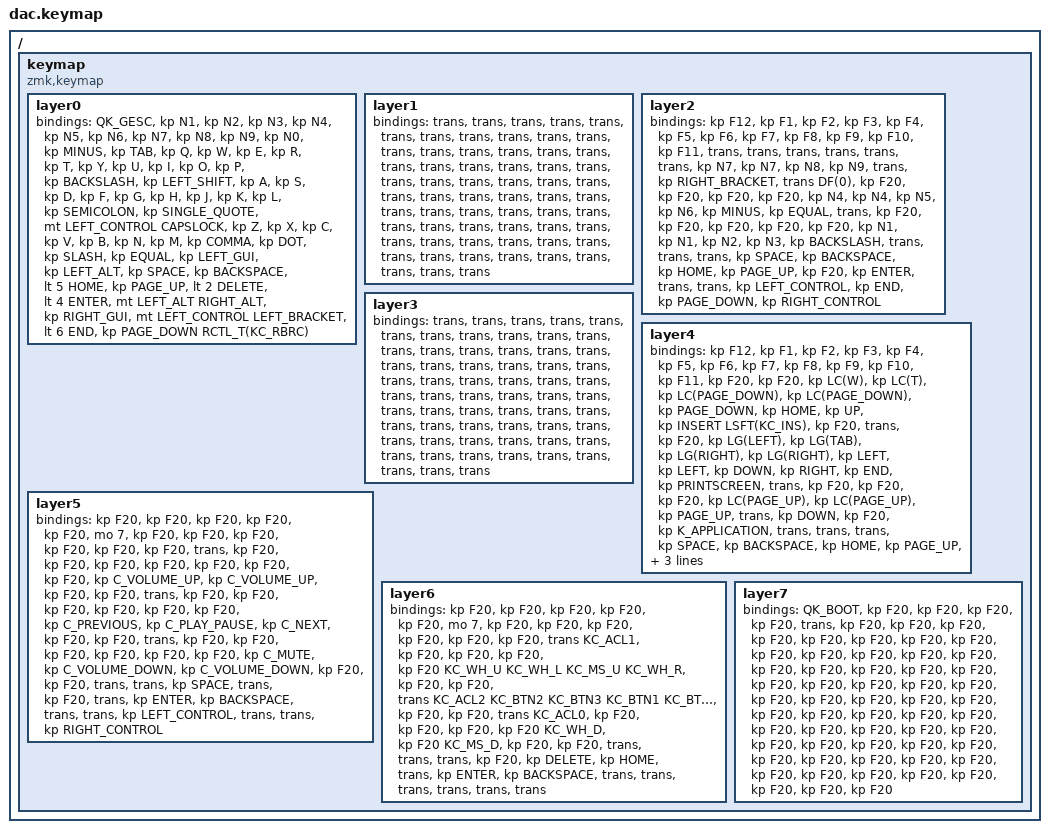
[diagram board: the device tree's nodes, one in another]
/*
  * Copyright (c) 2020 The ZMK Contributors
  *
  * SPDX-License-Identifier: MIT
  */

  #include <behaviors.dtsi>
  #include <dt-bindings/zmk/keys.h>
  #include <dt-bindings/zmk/bt.h>
  #include <dt-bindings/zmk/ext_power.h>

  / {
    keymap {
      compatible = "zmk,keymap";
  layer0 {
          bindings = <
          QK_GESC &kp N1 &kp N2 &kp N3 &kp N4 &kp N5 &kp N6 &kp N7 &kp N8 &kp N9 &kp N0 &kp MINUS &kp TAB &kp Q &kp W &kp E &kp R &kp T &kp Y &kp U &kp I &kp O &kp P &kp BACKSLASH &kp LEFT_SHIFT &kp A &kp S &kp D &kp F &kp G &kp H &kp J &kp K &kp L &kp SEMICOLON &kp SINGLE_QUOTE &mt LEFT_CONTROL CAPSLOCK &kp Z &kp X &kp C &kp V &kp B &kp N &kp M &kp COMMA &kp DOT &kp SLASH &kp EQUAL &kp LEFT_GUI &kp LEFT_ALT &kp SPACE &kp BACKSPACE &lt 5 HOME &kp PAGE_UP &lt 2 DELETE &lt 4 ENTER &mt LEFT_ALT RIGHT_ALT &kp RIGHT_GUI &mt LEFT_CONTROL LEFT_BRACKET &lt 6 END &kp PAGE_DOWN RCTL_T(KC_RBRC)
          >;
        };layer1 {
          bindings = <
          &trans &trans &trans &trans &trans &trans &trans &trans &trans &trans &trans &trans &trans &trans &trans &trans &trans &trans &trans &trans &trans &trans &trans &trans &trans &trans &trans &trans &trans &trans &trans &trans &trans &trans &trans &trans &trans &trans &trans &trans &trans &trans &trans &trans &trans &trans &trans &trans &trans &trans &trans &trans &trans &trans &trans &trans &trans &trans &trans &trans &trans &trans
          >;
        };layer2 {
          bindings = <
          &kp F12 &kp F1 &kp F2 &kp F3 &kp F4 &kp F5 &kp F6 &kp F7 &kp F8 &kp F9 &kp F10 &kp F11 &trans &trans &trans &trans &trans &trans &kp N7 &kp N7 &kp N8 &kp N9 &trans &kp RIGHT_BRACKET &trans DF(0) &kp F20 &kp F20 &kp F20 &kp F20 &kp N4 &kp N4 &kp N5 &kp N6 &kp MINUS &kp EQUAL &trans &kp F20 &kp F20 &kp F20 &kp F20 &kp F20 &kp N1 &kp N1 &kp N2 &kp N3 &kp BACKSLASH &trans &trans &trans &kp SPACE &kp BACKSPACE &kp HOME &kp PAGE_UP &kp F20 &kp ENTER &trans &trans &kp LEFT_CONTROL &kp END &kp PAGE_DOWN &kp RIGHT_CONTROL
          >;
        };layer3 {
          bindings = <
          &trans &trans &trans &trans &trans &trans &trans &trans &trans &trans &trans &trans &trans &trans &trans &trans &trans &trans &trans &trans &trans &trans &trans &trans &trans &trans &trans &trans &trans &trans &trans &trans &trans &trans &trans &trans &trans &trans &trans &trans &trans &trans &trans &trans &trans &trans &trans &trans &trans &trans &trans &trans &trans &trans &trans &trans &trans &trans &trans &trans &trans &trans
          >;
        };layer4 {
          bindings = <
          &kp F12 &kp F1 &kp F2 &kp F3 &kp F4 &kp F5 &kp F6 &kp F7 &kp F8 &kp F9 &kp F10 &kp F11 &kp F20 &kp F20 &kp LC(W) &kp LC(T) &kp LC(PAGE_DOWN) &kp LC(PAGE_DOWN) &kp PAGE_DOWN &kp HOME &kp UP &kp INSERT LSFT(KC_INS) &kp F20 &trans &kp F20 &kp LG(LEFT) &kp LG(TAB) &kp LG(RIGHT) &kp LG(RIGHT) &kp LEFT &kp LEFT &kp DOWN &kp RIGHT &kp END &kp PRINTSCREEN &trans &kp F20 &kp F20 &kp F20 &kp LC(PAGE_UP) &kp LC(PAGE_UP) &kp PAGE_UP &trans &kp DOWN &kp F20 &kp K_APPLICATION &trans &trans &trans &kp SPACE &kp BACKSPACE &kp HOME &kp PAGE_UP &kp DELETE &kp F20 &trans &trans &kp LEFT_CONTROL &kp END &kp PAGE_DOWN &kp RIGHT_CONTROL
          >;
        };layer5 {
          bindings = <
          &kp F20 &kp F20 &kp F20 &kp F20 &kp F20 &mo 7 &kp F20 &kp F20 &kp F20 &kp F20 &kp F20 &kp F20 &trans &kp F20 &kp F20 &kp F20 &kp F20 &kp F20 &kp F20 &kp F20 &kp C_VOLUME_UP &kp C_VOLUME_UP &kp F20 &kp F20 &trans &kp F20 &kp F20 &kp F20 &kp F20 &kp F20 &kp F20 &kp C_PREVIOUS &kp C_PLAY_PAUSE &kp C_NEXT &kp F20 &kp F20 &trans &kp F20 &kp F20 &kp F20 &kp F20 &kp F20 &kp F20 &kp C_MUTE &kp C_VOLUME_DOWN &kp C_VOLUME_DOWN &kp F20 &kp F20 &trans &trans &kp SPACE &trans &kp F20 &trans &kp ENTER &kp BACKSPACE &trans &trans &kp LEFT_CONTROL &trans &trans &kp RIGHT_CONTROL
          >;
        };layer6 {
          bindings = <
          &kp F20 &kp F20 &kp F20 &kp F20 &kp F20 &mo 7 &kp F20 &kp F20 &kp F20 &kp F20 &kp F20 &kp F20 &trans KC_ACL1 &kp F20 &kp F20 &kp F20 &kp F20 KC_WH_U KC_WH_L KC_MS_U KC_WH_R &kp F20 &kp F20 &trans KC_ACL2 KC_BTN2 KC_BTN3 KC_BTN1 KC_BTN1 KC_MS_L KC_MS_L KC_MS_D KC_MS_R &kp F20 &kp F20 &trans KC_ACL0 &kp F20 &kp F20 &kp F20 &kp F20 KC_WH_D &kp F20 KC_MS_D &kp F20 &kp F20 &trans &trans &trans &kp F20 &kp DELETE &kp HOME &trans &kp ENTER &kp BACKSPACE &trans &trans &trans &trans &trans &trans
          >;
        };layer7 {
          bindings = <
          QK_BOOT &kp F20 &kp F20 &kp F20 &kp F20 &trans &kp F20 &kp F20 &kp F20 &kp F20 &kp F20 &kp F20 &kp F20 &kp F20 &kp F20 &kp F20 &kp F20 &kp F20 &kp F20 &kp F20 &kp F20 &kp F20 &kp F20 &kp F20 &kp F20 &kp F20 &kp F20 &kp F20 &kp F20 &kp F20 &kp F20 &kp F20 &kp F20 &kp F20 &kp F20 &kp F20 &kp F20 &kp F20 &kp F20 &kp F20 &kp F20 &kp F20 &kp F20 &kp F20 &kp F20 &kp F20 &kp F20 &kp F20 &kp F20 &kp F20 &kp F20 &kp F20 &kp F20 &kp F20 &kp F20 &kp F20 &kp F20 &kp F20 &kp F20 &kp F20 &kp F20 &kp F20
          >;
        };
    };
  };
